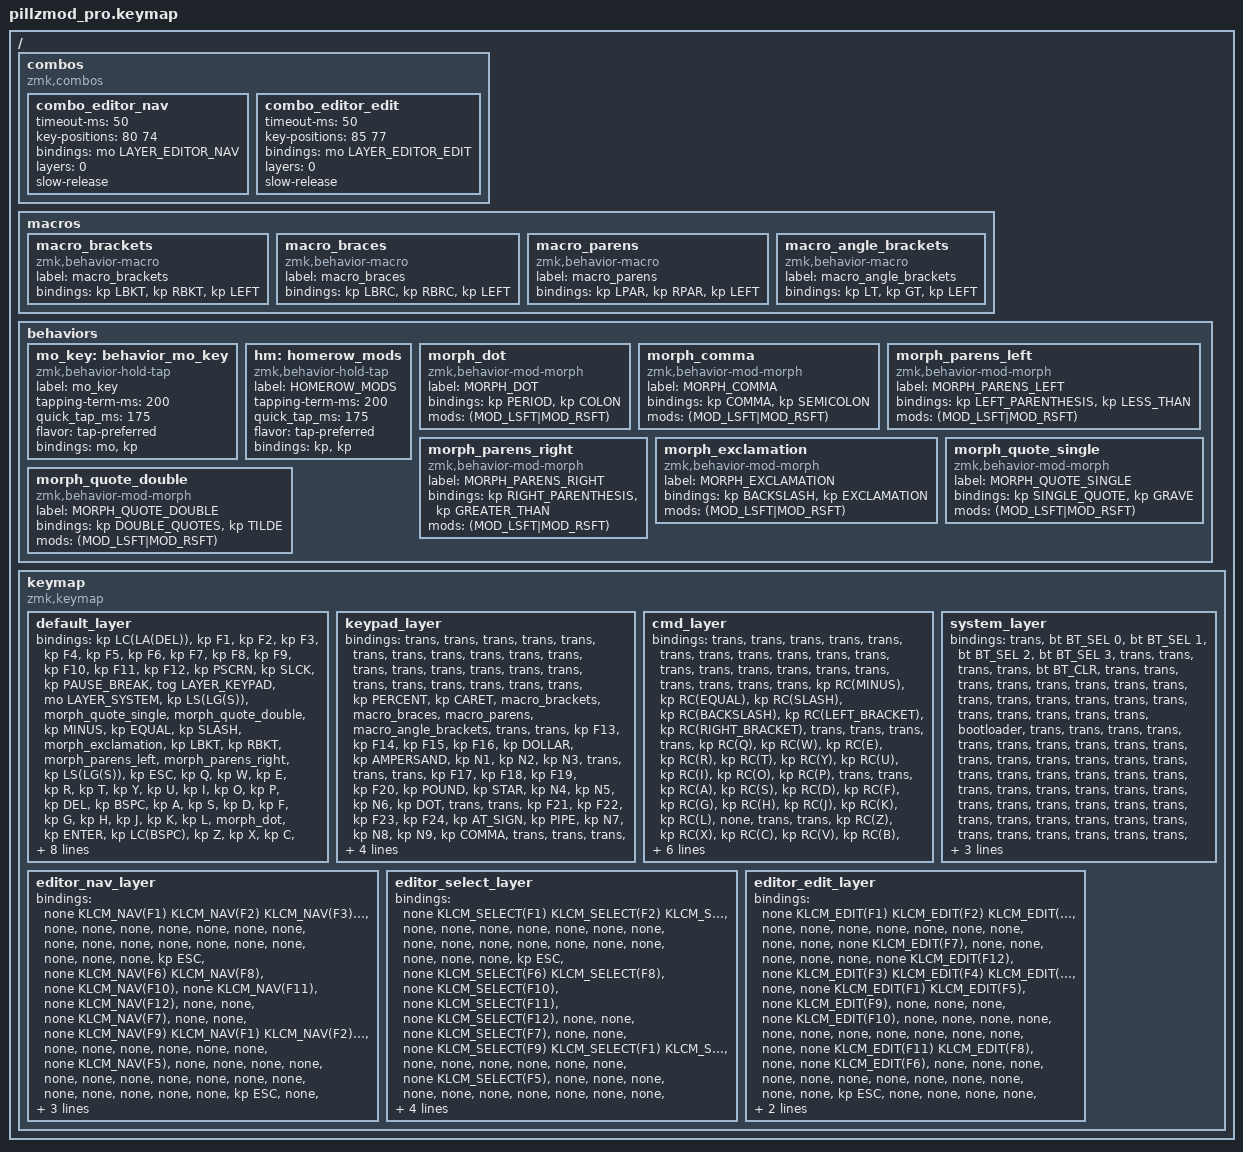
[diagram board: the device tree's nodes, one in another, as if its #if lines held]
/*
 * Copyright (c) 2020 The ZMK Contributors
 * 
 * SPDX-License-Identifier: MIT
 * 
 * ZMK keymap for Kinesis Advantage keyboards using Pillz Mod + Nice!Nano
 * Compatible with KLCM (Keyboard Layout Config Mapper)
 * 
 * Hardware: Kinesis Advantage with Pillz Mod Pro + Nice!Nano v2
 * Repository: https://github.com/masters3d/zmk-config-pillzmod-nicenano
 * Branch: cheyo
 */

#include <behaviors.dtsi>
#include <dt-bindings/zmk/keys.h>
#include <dt-bindings/zmk/bt.h>
#include <dt-bindings/zmk/outputs.h>

#define LAYER_KEYPAD 1
#define LAYER_CMD 2
#define LAYER_SYSTEM 3

// Opt-in pilot: define KLCM_EDITOR_ENABLE before preprocessing this keymap.
#ifdef KLCM_EDITOR_ENABLE
#define LAYER_EDITOR_NAV 4
#define LAYER_EDITOR_SELECT 5
#define LAYER_EDITOR_EDIT 6
#define KLCM_NAV(n) &kp LC(LA(n))
#define KLCM_SELECT(n) &kp LC(LA(LS(n)))
#define KLCM_EDIT(n) &kp LC(LS(n))
#endif

/ {
#ifdef KLCM_EDITOR_ENABLE
    // Same-hand Space + Keypad; release both keys to leave the access layer.
    // Keep the raw default keymap intact for KLCM's non-preprocessing parser.
    combos {
        compatible = "zmk,combos";
        combo_editor_nav {
            timeout-ms = <50>;
            key-positions = <80 74>;
            bindings = <&mo LAYER_EDITOR_NAV>;
            layers = <0>;
            slow-release;
        };
        combo_editor_edit {
            timeout-ms = <50>;
            key-positions = <85 77>;
            bindings = <&mo LAYER_EDITOR_EDIT>;
            layers = <0>;
            slow-release;
        };
    };
#endif
    macros {
        macro_brackets: macro_brackets {
            compatible = "zmk,behavior-macro";
            label = "macro_brackets";
            #binding-cells = <0>;
            bindings = <&kp LBKT>, <&kp RBKT>, <&kp LEFT>;
        };

        macro_braces: macro_braces {
            compatible = "zmk,behavior-macro";
            label = "macro_braces";
            #binding-cells = <0>;
            bindings = <&kp LBRC>, <&kp RBRC>, <&kp LEFT>;
        };

        macro_parens: macro_parens {
            compatible = "zmk,behavior-macro";
            label = "macro_parens";
            #binding-cells = <0>;
            bindings = <&kp LPAR>, <&kp RPAR>, <&kp LEFT>;
        };

        macro_angle_brackets: macro_angle_brackets {
            compatible = "zmk,behavior-macro";
            label = "macro_angle_brackets";
            #binding-cells = <0>;
            bindings = <&kp LT>, <&kp GT>, <&kp LEFT>;
        };
    };

    behaviors {
        mo_key: behavior_mo_key {
            compatible = "zmk,behavior-hold-tap";
            label = "mo_key";
            #binding-cells = <2>;
            tapping-term-ms = <200>;
            quick_tap_ms = <175>;
            flavor = "tap-preferred";
            bindings = <&mo>, <&kp>;
        };

        hm: homerow_mods {
            compatible = "zmk,behavior-hold-tap";
            label = "HOMEROW_MODS";
            #binding-cells = <2>;
            tapping-term-ms = <200>;
            quick_tap_ms = <175>;
            flavor = "tap-preferred";
            bindings = <&kp>, <&kp>;
        };

        // &dot_override,
        morph_dot: morph_dot {
            compatible = "zmk,behavior-mod-morph";
            label = "MORPH_DOT";
            #binding-cells = <0>;
            bindings = <&kp PERIOD>, <&kp COLON>;
            mods = <(MOD_LSFT|MOD_RSFT)>;
        };

        // &comma_override,
        morph_comma: morph_comma {
            compatible = "zmk,behavior-mod-morph";
            label = "MORPH_COMMA";
            #binding-cells = <0>;
            bindings = <&kp COMMA>, <&kp SEMICOLON>;
            mods = <(MOD_LSFT|MOD_RSFT)>;
        };

        // &parens_left_override,
        morph_parens_left: morph_parens_left {
            compatible = "zmk,behavior-mod-morph";
            label = "MORPH_PARENS_LEFT";
            #binding-cells = <0>;
            bindings = <&kp LEFT_PARENTHESIS>, <&kp LESS_THAN>;
            mods = <(MOD_LSFT|MOD_RSFT)>;
        };

        // &parens_right_override,
        morph_parens_right: morph_parens_right {
            compatible = "zmk,behavior-mod-morph";
            label = "MORPH_PARENS_RIGHT";
            #binding-cells = <0>;
            bindings = <&kp RIGHT_PARENTHESIS>, <&kp GREATER_THAN>;
            mods = <(MOD_LSFT|MOD_RSFT)>;
        };

        // &exclamation_override,
        morph_exclamation: morph_exclamation {
            compatible = "zmk,behavior-mod-morph";
            label = "MORPH_EXCLAMATION";
            #binding-cells = <0>;
            bindings = <&kp BACKSLASH>, <&kp EXCLAMATION>;
            mods = <(MOD_LSFT|MOD_RSFT)>;
        };

        // &quote_single_override,
        morph_quote_single: morph_quote_single {
            compatible = "zmk,behavior-mod-morph";
            label = "MORPH_QUOTE_SINGLE";
            #binding-cells = <0>;
            bindings = <&kp SINGLE_QUOTE>, <&kp GRAVE>;
            mods = <(MOD_LSFT|MOD_RSFT)>;
        };

        // &quote_double_override,
        morph_quote_double: morph_quote_double {
            compatible = "zmk,behavior-mod-morph";
            label = "MORPH_QUOTE_DOUBLE";
            #binding-cells = <0>;
            bindings = <&kp DOUBLE_QUOTES>, <&kp TILDE>;
            mods = <(MOD_LSFT|MOD_RSFT)>;
        };
    };

    keymap {
        compatible = "zmk,keymap";

        default_layer {
            // -----------------------------------------------------------------------------------------
            // CUSTOMIZED LAYOUT - Synced from adv360 with hardware-specific top row preserved
            // -----------------------------------------------------------------------------------------
            // |C-A-DEL|  F1  |  F2  |  F3  |  F4  |  F5  |  F6  |  F7  |  F8  |     |  F9  |  F10 |  F11 |  F12 | PSCRN| SLCK | PAUSE| Layer| SYS  |
            // |SCRNSH |  '   |  "   |  -   |  =   |  /   |                           |  !\  |  [   |  ]   | (<)  | (>)  |  -   |
            // | ESC   |  Q   |  W   |  E   |  R   |  T   |                           |  Y   |  U   |  I   |  O   |  P   | DEL  |
            // | BSPC  |  A   |  S   |  D   |  F   |  G   |                           |  H   |  J   |  K   |  L   | .(:) | ENTER|
            // |C-BSPC |  Z   |  X   |  C   |  V   |  B   |                           |  N   |  M   |  ,   |  .   | ,(;) | TAB  |
            //         | HOME | PGDN | PGUP | END  |      |                           |      | LEFT | DOWN |  UP  |RIGHT |
            //                                     |KYPAD | WIN  |               | ESC  |KYPAD |
            //                                            | CTRL |               | CTRL |
            //                              | SPC  | SHFT | ALT  |               | CMD  | SHFT | SPC  |
            //
            // Thumb Cluster Layout (unified across all keyboards):
            //
            //     Left Thumb Cluster              Right Thumb Cluster
            //     (Left hand)                     (Right hand)
            //     ┌───┬───┬───┐                   ┌───┬───┬───┐
            //     │L6 │L5 │L4 │                   │R4 │R5 │R6 │
            //     ├───┼───┼───┤                   ├───┼───┼───┤
            //     │L1 │L2 │L3 │                   │R3 │R2 │R1 │
            //     └───┴───┴───┘                   └───┴───┴───┘
            //    (thumb)  (far)                  (far)  (thumb)
            //
            // Position Mapping:
            //   L1=SPACE  L2=LSHIFT  L3=LALT  L4=LCTRL  L5=LWIN  L6=mo_KEYPAD
            //   R1=SPACE  R2=RSHIFT  R3=mo_CMD  R4=LCTRL  R5=ESC  R6=mo_KEYPAD
            //
            // pillzmod_pro Matrix Positions:
            //   Row 6 (after arrows): [L6:KEYPAD] [L5:WIN] ... [R5:ESC] [R6:KEYPAD]
            //   Row 7 (single key):              [L4:CTRL] ... [R4:CTRL]
            //   Row 8 (bottom):       [L1:SPC] [L2:LSHFT] [L3:LALT] | [R3:CMD] [R2:RSHFT] [R1:SPC]
            // -----------------------------------------------------------------------------------------
            //
            // Notes: 
            //   .(:) = morph_dot (Period → Colon when shifted)
            //   ,(;) = morph_comma (Comma → Semicolon when shifted)
            //   (<) = morph_parens_left (Left paren → Less than when shifted)
            //   (>) = morph_parens_right (Right paren → Greater than when shifted)
            //   !\  = morph_exclamation (Backslash → Exclamation when shifted)
            //   '   = morph_quote_single (Single quote → Grave when shifted)
            //   "   = morph_quote_double (Double quote → Tilde when shifted)
            //   SCRNSH = Shift+Cmd+S (screenshot shortcut)
            bindings = <
    &kp LC(LA(DEL))  &kp F1    &kp F2    &kp F3    &kp F4    &kp F5    &kp F6    &kp F7    &kp F8         &kp F9    &kp F10   &kp F11   &kp F12   &kp PSCRN  &kp SLCK  &kp PAUSE_BREAK  &tog LAYER_KEYPAD  &mo LAYER_SYSTEM
    &kp LS(LG(S)) &morph_quote_single  &morph_quote_double  &kp MINUS  &kp EQUAL  &kp SLASH                                       &morph_exclamation  &kp LBKT  &kp RBKT  &morph_parens_left  &morph_parens_right  &kp LS(LG(S))
    &kp ESC    &kp Q     &kp W     &kp E     &kp R     &kp T                                                                                     &kp Y     &kp U     &kp I     &kp O     &kp P     &kp DEL
    &kp BSPC    &kp A     &kp S     &kp D     &kp F     &kp G                                                                                     &kp H     &kp J     &kp K     &kp L     &morph_dot  &kp ENTER
    &kp LC(BSPC)  &kp Z   &kp X     &kp C     &kp V     &kp B                                                                                     &kp N     &kp M     &kp COMMA &kp DOT   &morph_comma  &kp TAB
               &kp HOME &kp PAGE_DOWN &kp PAGE_UP &kp END                                                                                   &kp LEFT  &kp DOWN  &kp UP    &kp RIGHT
                                                      &mo LAYER_KEYPAD  &kp LEFT_WIN                                       &kp ESC  &mo LAYER_KEYPAD
                                                                        &kp LEFT_CONTROL                                   &kp LEFT_CONTROL
                                        &kp SPACE   &kp LEFT_SHIFT      &kp LEFT_ALT                                       &mo LAYER_CMD  &kp RIGHT_SHIFT &kp SPACE
    &kp ESC  &kp X  &kp Z
            >;
        };
        
        keypad_layer {
            // -----------------------------------------------------------------------------------------
            // Keypad layer - Number pad with symbols and macros for brackets/braces
            bindings = <
    &trans  &trans  &trans  &trans  &trans  &trans  &trans  &trans  &trans                          &trans  &trans  &trans  &trans  &trans  &trans  &trans  &trans  &trans
    &trans  &trans  &trans  &trans  &trans  &kp PERCENT                                                              &kp CARET  &macro_brackets  &macro_braces  &macro_parens  &macro_angle_brackets  &trans
    &trans  &kp F13  &kp F14  &kp F15  &kp F16  &kp DOLLAR                                                           &kp AMPERSAND  &kp N1  &kp N2  &kp N3  &trans  &trans
    &trans  &kp F17  &kp F18  &kp F19  &kp F20  &kp POUND                                                            &kp STAR  &kp N4  &kp N5  &kp N6  &kp DOT  &trans
    &trans  &kp F21  &kp F22  &kp F23  &kp F24  &kp AT_SIGN                                                          &kp PIPE  &kp N7  &kp N8  &kp N9  &kp COMMA  &trans
            &trans  &trans  &trans  &trans                                                                                   &trans  &kp N0  &trans  &trans
                                                  &trans  &trans                                        &trans  &trans
                                                          &trans                                        &trans
                                          &trans  &trans  &trans                                        &trans  &trans  &trans
    &trans  &trans  &trans
            >;
        };

        cmd_layer {
            // -----------------------------------------------------------------------------------------
            // CMD/FN layer - Control/Command key combinations for all keys
            bindings = <
    &trans  &trans  &trans  &trans  &trans  &trans  &trans  &trans  &trans                          &trans  &trans  &trans  &trans  &trans  &trans  &trans  &trans  &trans
    &trans  &trans  &trans  &kp RC(MINUS)  &kp RC(EQUAL)  &kp RC(SLASH)                                      &kp RC(BACKSLASH)  &kp RC(LEFT_BRACKET)  &kp RC(RIGHT_BRACKET)  &trans  &trans  &trans
    &trans  &kp RC(Q)  &kp RC(W)  &kp RC(E)  &kp RC(R)  &kp RC(T)                                            &kp RC(Y)  &kp RC(U)  &kp RC(I)  &kp RC(O)  &kp RC(P)  &trans
    &trans  &kp RC(A)  &kp RC(S)  &kp RC(D)  &kp RC(F)  &kp RC(G)                                            &kp RC(H)  &kp RC(J)  &kp RC(K)  &kp RC(L)  &none  &trans
    &trans  &kp RC(Z)  &kp RC(X)  &kp RC(C)  &kp RC(V)  &kp RC(B)                                            &kp RC(N)  &kp RC(M)  &none  &none  &none  &trans
            &trans  &trans  &trans  &trans                                                                              &kp RC(LEFT)  &kp RC(DOWN)  &kp RC(UP)  &kp RC(RIGHT)
                                                  &trans  &trans                                        &trans  &trans
                                                          &trans                                        &trans
                                          &trans  &trans  &trans                                        &trans  &trans  &trans
    &trans  &trans  &trans
            >;
        };

        system_layer {
            // -----------------------------------------------------------------------------------------
            // System layer - Bluetooth, output selection, bootloader access
            bindings = <
    &trans  &bt BT_SEL 0  &bt BT_SEL 1  &bt BT_SEL 2  &bt BT_SEL 3  &trans  &trans  &trans  &trans       &bt BT_CLR  &trans  &trans  &trans  &trans  &trans  &trans  &trans  &trans
    &trans  &trans  &trans  &trans  &trans  &trans                                                                   &trans  &trans  &trans  &trans  &trans  &bootloader
    &trans  &trans  &trans  &trans  &trans  &trans                                                                   &trans  &trans  &trans  &trans  &trans  &trans
    &trans  &trans  &trans  &trans  &trans  &trans                                                                   &trans  &trans  &trans  &trans  &trans  &trans
    &trans  &trans  &trans  &trans  &trans  &trans                                                                   &trans  &trans  &trans  &trans  &trans  &trans
            &trans  &trans  &trans  &trans                                                                                   &trans  &trans  &trans  &trans
                                                  &trans  &trans                                        &trans  &trans
                                                          &trans                                        &trans
                                      &out OUT_TOG  &trans  &trans                                        &trans  &trans  &trans
    &trans  &trans  &trans
            >;
        };

#ifdef KLCM_EDITOR_ENABLE
        // H/J/K/L movement; hold either Shift position for anchored selection.
        // Unassigned positions are blocked; pedals and emergency Escape remain available.
        editor_nav_layer {
            bindings = <
    &none KLCM_NAV(F1) KLCM_NAV(F2) KLCM_NAV(F3) KLCM_NAV(F4) KLCM_NAV(F5) KLCM_NAV(F6) KLCM_NAV(F7) KLCM_NAV(F8) KLCM_NAV(F9) KLCM_NAV(F10) KLCM_NAV(F11) KLCM_NAV(F12) &none &none &none &none &none
    &none &none &none &none &none &none                                      &none &none &none &none &none &none
    &kp ESC &none KLCM_NAV(F6) KLCM_NAV(F8) &none KLCM_NAV(F10)               &none KLCM_NAV(F11) &none KLCM_NAV(F12) &none &none
    &none KLCM_NAV(F7) &none &none &none KLCM_NAV(F9)                        KLCM_NAV(F1) KLCM_NAV(F2) KLCM_NAV(F3) KLCM_NAV(F4) &none &none
    &none &none &none &none &none KLCM_NAV(F5)                              &none &none &none &none &none &none
    &none &none &none &none                                                &none &none &none &none
    &none &none                                                           &kp ESC &none
    &none                                                                 &none
    &trans &mo LAYER_EDITOR_SELECT &none                                   &none &mo LAYER_EDITOR_SELECT &mo LAYER_EDITOR_EDIT
    &trans &trans &trans
            >;
        };

        editor_select_layer {
            bindings = <
    &none KLCM_SELECT(F1) KLCM_SELECT(F2) KLCM_SELECT(F3) KLCM_SELECT(F4) KLCM_SELECT(F5) KLCM_SELECT(F6) KLCM_SELECT(F7) KLCM_SELECT(F8) KLCM_SELECT(F9) KLCM_SELECT(F10) KLCM_SELECT(F11) KLCM_SELECT(F12) &none &none &none &none &none
    &none &none &none &none &none &none                                      &none &none &none &none &none &none
    &kp ESC &none KLCM_SELECT(F6) KLCM_SELECT(F8) &none KLCM_SELECT(F10)      &none KLCM_SELECT(F11) &none KLCM_SELECT(F12) &none &none
    &none KLCM_SELECT(F7) &none &none &none KLCM_SELECT(F9)                  KLCM_SELECT(F1) KLCM_SELECT(F2) KLCM_SELECT(F3) KLCM_SELECT(F4) &none &none
    &none &none &none &none &none KLCM_SELECT(F5)                           &none &none &none &none &none &none
    &none &none &none &none                                                &none &none &none &none
    &none &none                                                           &kp ESC &none
    &none                                                                 &none
    &trans &trans &none                                                    &none &trans &mo LAYER_EDITOR_EDIT
    &trans &trans &trans
            >;
        };

        editor_edit_layer {
            bindings = <
    &none KLCM_EDIT(F1) KLCM_EDIT(F2) KLCM_EDIT(F3) KLCM_EDIT(F4) KLCM_EDIT(F5) KLCM_EDIT(F6) KLCM_EDIT(F7) KLCM_EDIT(F8) KLCM_EDIT(F9) KLCM_EDIT(F10) KLCM_EDIT(F11) KLCM_EDIT(F12) &none &none &none &none &none
    &none &none &none &none &none KLCM_EDIT(F7)                              &none &none &none &none &none &none
    KLCM_EDIT(F12) &none KLCM_EDIT(F3) KLCM_EDIT(F4) KLCM_EDIT(F2) &none     &none KLCM_EDIT(F1) KLCM_EDIT(F5) &none KLCM_EDIT(F9) &none
    &none &none &none KLCM_EDIT(F10) &none &none                            &none &none &none &none &none &none
    &none &none &none &none &none KLCM_EDIT(F11)                            KLCM_EDIT(F8) &none &none KLCM_EDIT(F6) &none &none
    &none &none &none &none                                                &none &none &none &none
    &none &none                                                           &kp ESC &none
    &none                                                                 &none
    &none &none &none                                                     &none &none &trans
    &trans &trans &trans
            >;
        };
#endif
    };
};
